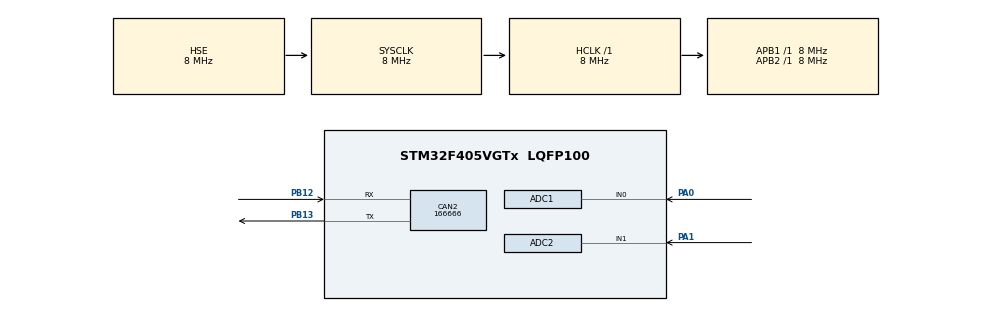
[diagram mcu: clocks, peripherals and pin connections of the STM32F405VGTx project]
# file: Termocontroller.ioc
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ADC1.Channel-0\#ChannelRegularConversion=ADC_CHANNEL_0
ADC1.ClockPrescaler=ADC_CLOCK_SYNC_PCLK_DIV4
ADC1.NbrOfConversionFlag=1
ADC1.Rank-0\#ChannelRegularConversion=1
ADC1.SamplingTime-0\#ChannelRegularConversion=ADC_SAMPLETIME_3CYCLES
ADC1.master=1
ADC2.Channel-0\#ChannelRegularConversion=ADC_CHANNEL_1
ADC2.ClockPrescaler=ADC_CLOCK_SYNC_PCLK_DIV4
ADC2.NbrOfConversionFlag=1
ADC2.Rank-0\#ChannelRegularConversion=1
ADC2.SamplingTime-0\#ChannelRegularConversion=ADC_SAMPLETIME_3CYCLES
CAN2.BS1=CAN_BS1_1TQ
CAN2.BS2=CAN_BS2_1TQ
CAN2.CalculateBaudRate=166666
CAN2.CalculateTimeBit=6000
CAN2.CalculateTimeQuantum=2000.0
Dma.ADC1.0.Direction=DMA_PERIPH_TO_MEMORY
Dma.ADC1.0.FIFOMode=DMA_FIFOMODE_DISABLE
Dma.ADC1.0.Instance=DMA2_Stream0
Dma.ADC1.0.MemDataAlignment=DMA_MDATAALIGN_HALFWORD
Dma.ADC1.0.MemInc=DMA_MINC_ENABLE
Dma.ADC1.0.Mode=DMA_NORMAL
Dma.ADC1.0.PeriphDataAlignment=DMA_PDATAALIGN_HALFWORD
Dma.ADC1.0.PeriphInc=DMA_PINC_DISABLE
Dma.ADC1.0.Priority=DMA_PRIORITY_LOW
Dma.ADC2.1.Direction=DMA_PERIPH_TO_MEMORY
Dma.ADC2.1.FIFOMode=DMA_FIFOMODE_DISABLE
Dma.ADC2.1.Instance=DMA2_Stream2
Dma.ADC2.1.MemDataAlignment=DMA_MDATAALIGN_HALFWORD
Dma.ADC2.1.MemInc=DMA_MINC_ENABLE
Dma.ADC2.1.Mode=DMA_NORMAL
Dma.ADC2.1.PeriphDataAlignment=DMA_PDATAALIGN_HALFWORD
Dma.ADC2.1.PeriphInc=DMA_PINC_DISABLE
Dma.ADC2.1.Priority=DMA_PRIORITY_LOW
Dma.Request0=ADC1
Dma.Request1=ADC2
FREERTOS.HEAP_NUMBER=3
FREERTOS.Tasks01=defaultTask,24,128,StartDefaultTask,Default,NULL,Dynamic,NULL,NULL;TaskNTC1,24,128,StartTaskNTC1,Default,NULL,Dynamic,NULL,NULL;TaskNTC2,24,128,StartTaskNTC2,Default,NULL,Dynamic,NULL,NULL
Mcu.Family=STM32F4
Mcu.Name=STM32F405VGTx
Mcu.Package=LQFP100
NVIC.DMA2_Stream0_IRQn=true\:5\:0\:false\:false\:true\:true\:false\:true\:true
NVIC.DMA2_Stream2_IRQn=true\:5\:0\:false\:false\:true\:true\:false\:true\:true
NVIC.PriorityGroup=NVIC_PRIORITYGROUP_4
NVIC.TIM2_IRQn=true\:15\:0\:false\:false\:true\:false\:false\:true\:true
NVIC.TimeBase=TIM2_IRQn
NVIC.TimeBaseIP=TIM2
PA0-WKUP.Signal=ADCx_IN0
PA1.Signal=ADCx_IN1
PB12.Mode=CAN_Activate
PB12.Signal=CAN2_RX
PB13.Mode=CAN_Activate
PB13.Signal=CAN2_TX
PH0-OSC_IN.Mode=HSE-External-Oscillator
PH0-OSC_IN.Signal=RCC_OSC_IN
PH1-OSC_OUT.Mode=HSE-External-Oscillator
PH1-OSC_OUT.Signal=RCC_OSC_OUT
ProjectManager.HeapSize=0x200
ProjectManager.StackSize=0x400
ProjectManager.TargetToolchain=CMake
RCC.48MHZClocksFreq_Value=48000000
RCC.AHBFreq_Value=8000000
RCC.APB1Freq_Value=8000000
RCC.APB1TimFreq_Value=8000000
RCC.APB2Freq_Value=8000000
RCC.APB2TimFreq_Value=8000000
RCC.CortexFreq_Value=8000000
RCC.HCLKFreq_Value=8000000
RCC.HSE_VALUE=8000000
RCC.HSI_VALUE=16000000
RCC.LSE_VALUE=32768
RCC.PLLM=8
RCC.PLLSourceVirtual=RCC_PLLSOURCE_HSE
RCC.SYSCLKFreq_VALUE=8000000
RCC.SYSCLKSource=RCC_SYSCLKSOURCE_HSE
RCC.VCOOutputFreq_Value=192000000
SH.ADCx_IN0.0=ADC1_IN0,IN0
SH.ADCx_IN1.0=ADC2_IN1,IN1
VP_FREERTOS_VS_CMSIS_V2.Mode=CMSIS_V2
VP_SYS_VS_tim2.Mode=TIM2
board=custom

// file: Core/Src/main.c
/* USER CODE BEGIN Header */
/**
  ******************************************************************************
  * @file           : main.c
  * @brief          : Main program body
  ******************************************************************************
  * @attention
  *
  * Copyright (c) 2024 STMicroelectronics.
  * All rights reserved.
  *
  * This software is licensed under terms that can be found in the LICENSE file
  * in the root directory of this software component.
  * If no LICENSE file comes with this software, it is provided AS-IS.
  *
  ******************************************************************************
  */
/* USER CODE END Header */
#include "main.h"
#include "cmsis_os.h"
#include "adc.h"
#include "can.h"
#include "dma.h"
#include "gpio.h"

void SystemClock_Config(void);
void MX_FREERTOS_Init(void);

int main(void)
{
  /* Reset of all peripherals, Initializes the Flash interface and the Systick. */
  HAL_Init();

  /* Configure the system clock */
  SystemClock_Config();

  /* Initialize all configured peripherals */
  MX_GPIO_Init();
  MX_DMA_Init();
  MX_ADC1_Init();
  MX_ADC2_Init();
  MX_CAN2_Init();

  /* Init scheduler */
  osKernelInitialize();

  /* Call init function for freertos objects (in cmsis_os2.c) */
  MX_FREERTOS_Init();

  /* Start scheduler */
  osKernelStart();

  /* We should never get here as control is now taken by the scheduler */

  /* Infinite loop */
  /* USER CODE BEGIN WHILE */
  while (1)
  {

  }
  /* USER CODE END 3 */
}

void SystemClock_Config(void)
{
  RCC_OscInitTypeDef RCC_OscInitStruct = {0};
  RCC_ClkInitTypeDef RCC_ClkInitStruct = {0};

  /** Configure the main internal regulator output voltage
  */
  __HAL_RCC_PWR_CLK_ENABLE();
  __HAL_PWR_VOLTAGESCALING_CONFIG(PWR_REGULATOR_VOLTAGE_SCALE1);

  /** Initializes the RCC Oscillators according to the specified parameters
  * in the RCC_OscInitTypeDef structure.
  */
  RCC_OscInitStruct.OscillatorType = RCC_OSCILLATORTYPE_HSE;
  RCC_OscInitStruct.HSEState = RCC_HSE_ON;
  RCC_OscInitStruct.PLL.PLLState = RCC_PLL_NONE;
  if (HAL_RCC_OscConfig(&RCC_OscInitStruct) != HAL_OK)
  {
    Error_Handler();
  }

  /** Initializes the CPU, AHB and APB buses clocks
  */
  RCC_ClkInitStruct.ClockType = RCC_CLOCKTYPE_HCLK|RCC_CLOCKTYPE_SYSCLK
                              |RCC_CLOCKTYPE_PCLK1|RCC_CLOCKTYPE_PCLK2;
  RCC_ClkInitStruct.SYSCLKSource = RCC_SYSCLKSOURCE_HSE;
  RCC_ClkInitStruct.AHBCLKDivider = RCC_SYSCLK_DIV1;
  RCC_ClkInitStruct.APB1CLKDivider = RCC_HCLK_DIV1;
  RCC_ClkInitStruct.APB2CLKDivider = RCC_HCLK_DIV1;

  if (HAL_RCC_ClockConfig(&RCC_ClkInitStruct, FLASH_LATENCY_0) != HAL_OK)
  {
    Error_Handler();
  }
}

void HAL_TIM_PeriodElapsedCallback(TIM_HandleTypeDef *htim)
{
  if (htim->Instance == TIM2) {
    HAL_IncTick();
  }
}

void Error_Handler(void)
{
  __disable_irq();
  while (1)
  {
  }
}

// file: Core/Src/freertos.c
/* USER CODE BEGIN Header */
/**
  ******************************************************************************
  * File Name          : freertos.c
  * Description        : Code for freertos applications
  ******************************************************************************
  * @attention
  *
  * Copyright (c) 2024 STMicroelectronics.
  * All rights reserved.
  *
  * This software is licensed under terms that can be found in the LICENSE file
  * in the root directory of this software component.
  * If no LICENSE file comes with this software, it is provided AS-IS.
  *
  ******************************************************************************
  */
/* USER CODE END Header */

#include "FreeRTOS.h"
#include "task.h"
#include "main.h"
#include "cmsis_os.h"
#include "termo_sensor.h"

#define NTC1  1
#define NTC2  2

extern void get_adc_data(uint8_t ntc);
extern void CAN_send_data(int8_t data1, int8_t data2);

/* Definitions for defaultTask */
osThreadId_t defaultTaskHandle;
const osThreadAttr_t defaultTask_attributes = {
  .name = "defaultTask",
  .stack_size = 128 * 4,
  .priority = (osPriority_t) osPriorityNormal,
};
/* Definitions for TaskNTC1 */
osThreadId_t TaskNTC1Handle;
const osThreadAttr_t TaskNTC1_attributes = {
  .name = "TaskNTC1",
  .stack_size = 128 * 4,
  .priority = (osPriority_t) osPriorityNormal,
};
/* Definitions for TaskNTC2 */
osThreadId_t TaskNTC2Handle;
const osThreadAttr_t TaskNTC2_attributes = {
  .name = "TaskNTC2",
  .stack_size = 128 * 4,
  .priority = (osPriority_t) osPriorityNormal,
};

void StartDefaultTask(void *argument);
void StartTaskNTC1(void *argument);
void StartTaskNTC2(void *argument);

void MX_FREERTOS_Init(void); /* (MISRA C 2004 rule 8.1) */

void MX_FREERTOS_Init(void) {

  /* Create the thread(s) */
  /* creation of defaultTask */
  defaultTaskHandle = osThreadNew(StartDefaultTask, NULL, &defaultTask_attributes);

  /* creation of TaskNTC1 */
  TaskNTC1Handle = osThreadNew(StartTaskNTC1, NULL, &TaskNTC1_attributes);

  /* creation of TaskNTC2 */
  TaskNTC2Handle = osThreadNew(StartTaskNTC2, NULL, &TaskNTC2_attributes);

}

void StartDefaultTask(void *argument)
{
  int8_t temp_ntc1=0;
  int8_t temp_ntc2=0;
  for(;;)
  {
    temp_ntc1 = aggregate_data(NTC1);
    temp_ntc2 = aggregate_data(NTC2);
    CAN_send_data(temp_ntc1, temp_ntc2);
    osDelay(100);
  }
  /* USER CODE END StartDefaultTask */
}

void StartTaskNTC1(void *argument)
{
  /* USER CODE BEGIN StartTaskNTC1 */
  /* Infinite loop */
  for(;;)
  {
    get_adc_data(NTC1);
    osDelay(10);
  }
  /* USER CODE END StartTaskNTC1 */
}

void StartTaskNTC2(void *argument)
{
  /* USER CODE BEGIN StartTaskNTC2 */
  /* Infinite loop */
  for(;;)
  {
    get_adc_data(NTC2);
    osDelay(10);
  }
  /* USER CODE END StartTaskNTC2 */
}
